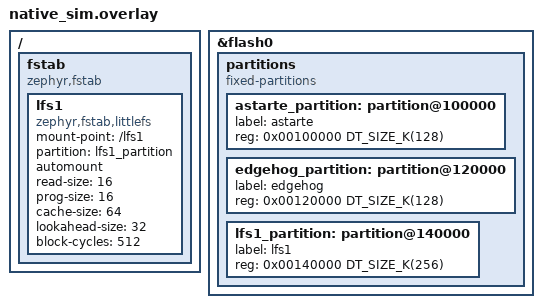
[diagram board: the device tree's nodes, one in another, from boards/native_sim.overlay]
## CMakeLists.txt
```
# (C) Copyright 2024, SECO Mind Srl
#
# SPDX-License-Identifier: Apache-2.0

cmake_minimum_required(VERSION 3.20.0)

function(concat_if_exists FILE_PATH STRING_NAME)
    # Check if the file exists
    file(GLOB FILE_TO_ADD ${FILE_PATH})

    # If the file exists, add it to the list
    if(EXISTS ${FILE_TO_ADD})
        set(${STRING_NAME} "${${STRING_NAME}};${FILE_PATH}" PARENT_SCOPE)
    endif()
endfunction()

set(CMAKE_EXPORT_COMPILE_COMMANDS ON)

# add some custom functions from the sample directory
set(SAMPLE_DIR "${CMAKE_CURRENT_LIST_DIR}/../samples/edgehog_app")

# add the sample specific private configuration
concat_if_exists(${CMAKE_SOURCE_DIR}/private.conf EXTRA_CONF_FILE)

find_package(Zephyr REQUIRED HINTS $ENV{ZEPHYR_BASE})
project(e2e_test)

if(CONFIG_FILE_SYSTEM_LITTLEFS)
    zephyr_library_link_libraries(LITTLEFS)
endif()

# add sources and includes from the sample dir
target_sources(app PRIVATE ${SAMPLE_DIR}/src/eth.c)
target_include_directories(app PRIVATE ${SAMPLE_DIR}/src/include)

# Generate the key/certificate pair for the HTTP server if not already present
set(CERT_OUT "${CMAKE_CURRENT_SOURCE_DIR}/${CONFIG_E2E_HTTP_SERVER_CERT_DIR}/192.0.2.2.pem")
set(KEY_OUT "${CMAKE_CURRENT_SOURCE_DIR}/${CONFIG_E2E_HTTP_SERVER_CERT_DIR}/192.0.2.2.key")
set(CERT_CONFIG "${CMAKE_CURRENT_SOURCE_DIR}/${CONFIG_E2E_HTTP_SERVER_CERT_DIR}/cert_config.cnf")

message(STATUS "Generating self-signed certificate and key...")
execute_process(
    COMMAND openssl req -x509 -new -nodes
            -keyout "${KEY_OUT}"
            -out "${CERT_OUT}"
            -days 3650
            -config "${CERT_CONFIG}"
    RESULT_VARIABLE openssl_result
)
if(NOT openssl_result EQUAL "0")
    message(FATAL_ERROR "Failed to generate certificates with OpenSSL")
endif()

# handle generating certificate inc file
include(certificate.cmake)
if(CONFIG_E2E_ASTARTE_TLS_CERTIFICATE_PATH)
    generate_certificate_inc(${CONFIG_E2E_ASTARTE_TLS_CERTIFICATE_PATH} "astarte_root_certificate")
endif()
if(CONFIG_E2E_EDGEHOG_OTA_TLS_CERTIFICATE_PATH)
    generate_certificate_inc(${CONFIG_E2E_EDGEHOG_OTA_TLS_CERTIFICATE_PATH} "edgehog_ota_root_certificate")
endif()
generate_certificate_inc("${CONFIG_E2E_HTTP_SERVER_CERT_DIR}/192.0.2.2.pem" "edgehog_ft_root_certificate")

# add astarte private headers
target_include_directories(app PRIVATE ${CMAKE_SOURCE_DIR}/../lib/edgehog_device/include)

# add sources
FILE(GLOB app_sources src/*.c)
target_sources(app PRIVATE ${app_sources})
target_include_directories(app PRIVATE include)
```

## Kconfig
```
# (C) Copyright 2024, SECO Mind Srl
#
# SPDX-License-Identifier: Apache-2.0

menu "Zephyr"
source "Kconfig.zephyr"
endmenu

rsource "../Kconfig"

menu "End to end test"

config E2E_ASTARTE_TLS_CERTIFICATE_PATH
	string "Path of the tls root Astarte certificate"
	help
	  Path to a certificate in PEM format. It will be included in the binary and used for TLS
	  authentication with Astarte.
	  This path should be relative to the end to end project folder.

config E2E_EDGEHOG_OTA_TLS_CERTIFICATE_PATH
	string "Path of the tls root Edgehog certificate for OTA"
	help
	  Path to a certificate in PEM format. It will be included in the binary and used for TLS
	  authentication with Edgehog.
	  This path should be relative to the end to end project folder.

config E2E_ASTARTE_DEVICE_ID
	string "Astarte device ID"
    default ""
	help
	  Device ID to be used to connect to Astarte.

config E2E_ASTARTE_CREDENTIAL_SECRET
    string "Astarte credential secret"
    default ""
    help
        The credential secret to be used to connect to Astarte.

config E2E_HTTP_SERVER_DATA_DIR
    string "Directory for HTTP server data"
    default "http_server_data"
    help
        Directory where the HTTP server will store its data.

config E2E_HTTP_SERVER_CERT_DIR
    string "Directory for HTTP server certificates"
    default "http_server_certs"
    help
        Directory where the HTTP server will store its certificates.

config E2E_HTTP_SERVER_PORT
    int "HTTP server port"
    default 8443
    help
        Port on which the HTTP server will listen.

config E2E_APPENGINE_TOKEN
	string "Token to access appengine APIs"
    default ""
	help
	  Token used to access the Astarte appengine APIs.

config E2E_APPENGINE_URL
    string "Url of the appengine APIs"
    default ""
    help
        Url of the appengine APIs exposed by astarte

config E2E_LOG_ONLY
    bool "Enable device log only mode"
    default n
    help
        Incoming astarte server messages will only be logged and no check will be
        performed against incoming data

config E2E_DEVICE_THREAD_STACK_SIZE
    int "Device thread stack size (Bytes)"
    default 8192
    help
        Use this setting to change the size of the stack for the thread running the Astarte device.

config E2E_DEVICE_THREAD_PRIORITY
    int "Device thread priority"
    default 0
    help
        Use this setting to change the priority of the thread running the Astarte device.

config E2E_ETH_POLL_PERIOD_MS
    int "Device thread polling period (ms)"
    default 100
    help
        Use this setting to change the polling period for the ethernet connection.

config E2E_MQTT_CONNECTION_TIMEOUT_MS
    int "MQTT connection timeout (ms)"
    default 3000
    help
        Use this setting to change the MQTT connection timeout.

config E2E_MQTT_POLL_TIMEOUT_MS
    int "MQTT subsequent polling timeout (ms)"
    default 200
    help
        Use this setting to change the MQTT polling timeout.

config E2E_HTTP_TIMEOUT_MS
    int "HTTP operations timeout (ms)"
    default 3000
    help
        Use this setting to change the timeout for HTTP requests.

menu "Logging options"

module = APP
module-str = APP
source "subsys/logging/Kconfig.template.log_config"

module = RUNNER
module-str = Log level for e2e runner and command handler
module-help = Sets log level for e2e runner and command handler
source "subsys/logging/Kconfig.template.log_config"

module = UTILITIES
module-str = Log level for e2e utilities functions
module-help = Sets log level for e2e utilities functions
source "subsys/logging/Kconfig.template.log_config"

module = SHELL_HANDLERS
module-str = Log level for shell handlers
module-help = Sets log level for zephyr shell handlers
source "subsys/logging/Kconfig.template.log_config"

module = DEVICE_HANDLER
module-str = Log level for device handler
module-help = Sets log level for zephyr device handler
source "subsys/logging/Kconfig.template.log_config"

endmenu

endmenu
```

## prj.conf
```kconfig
# (C) Copyright 2024, SECO Mind Srl
#
# SPDX-License-Identifier: Apache-2.0
#
# This is a Kconfig fragment which can be used to enable debug-related options
# in the application. See the README for more details.

# Increase size for heap allocation space
CONFIG_COMMON_LIBC_MALLOC_ARENA_SIZE=196608

# Increase the UART RX ring buffer to handle long automated commands
CONFIG_SHELL_BACKEND_SERIAL_RX_RING_BUFFER_SIZE=1024
# Ensure the shell command buffer is large enough
CONFIG_SHELL_CMD_BUFF_SIZE=1024
# Prevent the terminal from line-wrapping the echo, which breaks Twister's regex
CONFIG_SHELL_DEFAULT_TERMINAL_WIDTH=1024

# Increase the system workqueue stack
CONFIG_SYSTEM_WORKQUEUE_STACK_SIZE=4096

CONFIG_SHELL=y
CONFIG_SHELL_BACKEND_SERIAL=y
CONFIG_SHELL_BACKEND_SERIAL_LOG_LEVEL_DBG=y

CONFIG_E2E_ASTARTE_TLS_CERTIFICATE_PATH="certificate/astarte.pem"
CONFIG_E2E_EDGEHOG_OTA_TLS_CERTIFICATE_PATH="certificate/edgehog-ota.pem"

CONFIG_DEBUG_OPTIMIZATIONS=y
CONFIG_MBEDTLS_DEBUG=y

# Enable logging with floating point support
CONFIG_LOG=y
CONFIG_CBPRINTF_FP_SUPPORT=y

# Increase minimum heap size.
# TODO: set back the value to 4096 once the file transfer download will not require heap allocation
CONFIG_HEAP_MEM_POOL_SIZE=12288

# Increased stack size
CONFIG_MAIN_STACK_SIZE=16384

# Use custom heap
CONFIG_ASTARTE_DEVICE_SDK_ENABLE_HEAP=y

# Enable base64 encoding and decoding
CONFIG_BASE64=y

# Enable system hashmaps
CONFIG_SYS_HASH_MAP=y
CONFIG_SYS_HASH_FUNC32=y

# Enable JSON library
CONFIG_JSON_LIBRARY=y

# Enable entropy generator
CONFIG_ENTROPY_GENERATOR=y

# DNS resolver
CONFIG_DNS_RESOLVER=y
CONFIG_DNS_SERVER_IP_ADDRESSES=y
CONFIG_DNS_SERVER1="8.8.8.8" # Google DNS

# Base MbedTLS & heap configuration
CONFIG_MBEDTLS=y
CONFIG_MBEDTLS_BUILTIN=y
CONFIG_MBEDTLS_ENABLE_HEAP=y
CONFIG_MBEDTLS_HEAP_SIZE=95000

# Enable PSA Crypto Backend
CONFIG_PSA_CRYPTO=y
CONFIG_PSA_CRYPTO_ENABLE_ALL=y
CONFIG_MBEDTLS_PSA_CRYPTO_C=y

# TLS & X.509
CONFIG_MBEDTLS_SSL_MAX_CONTENT_LEN=8192
CONFIG_MBEDTLS_PEM_PARSE_C=y
CONFIG_MBEDTLS_PEM_WRITE_C=y
CONFIG_MBEDTLS_BASE64_C=y
CONFIG_MBEDTLS_PK_WRITE_C=y
CONFIG_MBEDTLS_SSL_PROTO_TLS1_2=y
CONFIG_MBEDTLS_SSL_SERVER_NAME_INDICATION=y
CONFIG_MBEDTLS_X509_USE_C=y
CONFIG_MBEDTLS_X509_CRT_PARSE_C=y
CONFIG_MBEDTLS_X509_CRL_PARSE_C=y
CONFIG_MBEDTLS_X509_CSR_PARSE_C=y
CONFIG_MBEDTLS_X509_CSR_WRITE_C=y
CONFIG_MBEDTLS_PKCS5_C=y
CONFIG_MBEDTLS_KEY_EXCHANGE_ECDHE_ECDSA_ENABLED=y
CONFIG_MBEDTLS_KEY_EXCHANGE_ECDHE_RSA_ENABLED=y

# Enable networking
CONFIG_NETWORKING=y

# Sockets
CONFIG_NET_SOCKETS=y
CONFIG_NET_SOCKETS_SOCKOPT_TLS=y

# Use DHCP for IPv4 and IPv6
CONFIG_NET_DHCPV4=y
CONFIG_NET_DHCPV6=y

# Generic networking options
CONFIG_NET_TX_STACK_SIZE=4096
CONFIG_NET_RX_STACK_SIZE=4096
CONFIG_NET_PKT_RX_COUNT=20
CONFIG_NET_PKT_TX_COUNT=20
CONFIG_NET_BUF_RX_COUNT=40
CONFIG_NET_BUF_TX_COUNT=40
CONFIG_NET_MAX_CONTEXTS=20
CONFIG_NET_MAX_CONN=6
CONFIG_NET_MGMT=y
CONFIG_NET_MGMT_EVENT=y
CONFIG_NET_IPV4=y
CONFIG_NET_IPV6=y
CONFIG_NET_TCP=y

# Enable HTTP client
CONFIG_HTTP_CLIENT=y

# MQTT options
CONFIG_MQTT_LIB=y
CONFIG_MQTT_LIB_TLS=y
CONFIG_MQTT_KEEPALIVE=60

# Enable flash
CONFIG_FLASH=y
CONFIG_FLASH_MAP=y
CONFIG_FLASH_PAGE_LAYOUT=y

# Enable NVS
CONFIG_NVS=y
CONFIG_NVS_LOG_LEVEL_WRN=y

# Enable storage
CONFIG_ZMS=y
CONFIG_ZMS_LOG_LEVEL_WRN=y

# Enable hash functions
CONFIG_SYS_HASH_FUNC32=y
CONFIG_SYS_HASH_FUNC32_MURMUR3=y

# Astarte device SDK
CONFIG_ASTARTE_DEVICE_SDK=y
CONFIG_ASTARTE_DEVICE_SDK_HOSTNAME="."
# The two certificate tags are the same as the root CA is the same for Astarte API and MQTT broker.
CONFIG_ASTARTE_DEVICE_SDK_HTTPS_CA_CERT_TAG=1
CONFIG_ASTARTE_DEVICE_SDK_MQTTS_CA_CERT_TAG=1
CONFIG_ASTARTE_DEVICE_SDK_CLIENT_CERT_TAG=2
CONFIG_ASTARTE_DEVICE_SDK_PAIRING_JWT=""
CONFIG_ASTARTE_DEVICE_SDK_REALM_NAME="."

# Edgehog depends on
CONFIG_IMG_MANAGER=y
CONFIG_STREAM_FLASH=y
CONFIG_REBOOT=y

# Edgehog device
CONFIG_EDGEHOG_DEVICE=y
CONFIG_EDGEHOG_DEVICE_OTA_HTTPS_CA_CERT_TAG=3
CONFIG_EDGEHOG_DEVICE_ZBUS_OTA_EVENT=y

# System info interface data
CONFIG_EDGEHOG_DEVICE_PART_NUMBER=""
CONFIG_EDGEHOG_DEVICE_SERIAL_NUMBER=""

# Sample configuration
CONFIG_E2E_ASTARTE_CREDENTIAL_SECRET="."
CONFIG_E2E_ASTARTE_DEVICE_ID="......................"

CONFIG_DNS_RESOLVER_AI_MAX_ENTRIES=4
CONFIG_NET_SOCKETS_TLS_MAX_CONTEXTS=4
CONFIG_TLS_MAX_CREDENTIALS_NUMBER=8

CONFIG_THREAD_MONITOR=y
CONFIG_INIT_STACKS=y
CONFIG_THREAD_STACK_INFO=y

CONFIG_ZVFS_OPEN_MAX=26

CONFIG_SNTP=y
CONFIG_NET_CONFIG_CLOCK_SNTP_INIT=y
CONFIG_NET_CONFIG_SNTP_INIT_SERVER="0.pool.ntp.org"
CONFIG_NET_CONFIG_SNTP_INIT_TIMEOUT=3000

# Enable the settings
CONFIG_SETTINGS=y

# Activate Zbus
CONFIG_ZBUS=y

# Activate thread naming
CONFIG_THREAD_NAME=y

# Enable File System and LittleFS
CONFIG_FILE_SYSTEM=y
CONFIG_FILE_SYSTEM_LITTLEFS=y

# Enable UUID
CONFIG_UUID=y
CONFIG_UUID_V4=y
CONFIG_UUID_V5=y
CONFIG_UUID_BASE64=y

# Enable LZ4 compression
CONFIG_LZ4=y
CONFIG_LZ4_FRAME_SUPPORT=y

# Enable scoped cleanup helpers
CONFIG_SCOPE_CLEANUP_HELPERS=y
```

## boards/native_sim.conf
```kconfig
# (C) Copyright 2024, SECO Mind Srl
#
# SPDX-License-Identifier: Apache-2.0

CONFIG_LOG_BACKEND_NATIVE_POSIX=n
CONFIG_UART_NATIVE_PTY_0_ON_STDINOUT=y

CONFIG_PICOLIBC_USE_MODULE=y
CONFIG_PICOLIBC=y

# Print logs immediately to catch fatal errors before exit
CONFIG_LOG_MODE_IMMEDIATE=y

# Ethernet settings
CONFIG_NET_L2_ETHERNET=y
CONFIG_NET_L2_ETHERNET_MGMT=y

# Network application options and configuration
CONFIG_NET_DHCPV4=n
CONFIG_NET_DHCPV6=n
CONFIG_NET_CONFIG_SETTINGS=y
CONFIG_NET_CONFIG_NEED_IPV6=y
CONFIG_NET_CONFIG_MY_IPV6_ADDR="2001:db8::1"
CONFIG_NET_CONFIG_PEER_IPV6_ADDR="2001:db8::2"
CONFIG_NET_CONFIG_NEED_IPV4=y
CONFIG_NET_CONFIG_MY_IPV4_ADDR="192.0.2.1"
CONFIG_NET_CONFIG_PEER_IPV4_ADDR="192.0.2.2"
CONFIG_NET_CONFIG_MY_IPV4_GW="192.0.2.2"
```

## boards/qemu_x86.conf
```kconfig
# (C) Copyright 2026, SECO Mind Srl
#
# SPDX-License-Identifier: Apache-2.0

# Provide enough stack space for MbedTLS crypto and HTTPS handshakes
CONFIG_E2E_DEVICE_THREAD_STACK_SIZE=16384
CONFIG_SHELL_STACK_SIZE=16384

# Enable the simulated flash driver for NVS
CONFIG_FLASH_SIMULATOR=y

# Print logs immediately to catch fatal errors before exit
CONFIG_LOG_MODE_IMMEDIATE=y

# Enable PCIe bus to support the e1000 driver
CONFIG_PCIE=y

# QEMU Ethernet settings (emulated e1000)
CONFIG_NET_L2_ETHERNET=y
CONFIG_ETH_E1000=y

# Enable the QEMU network backend
CONFIG_NET_QEMU_ETHERNET=y

# Network application options and configuration
CONFIG_NET_DHCPV4=n
CONFIG_NET_DHCPV6=n
CONFIG_NET_CONFIG_SETTINGS=y
CONFIG_NET_CONFIG_NEED_IPV6=y
CONFIG_NET_CONFIG_MY_IPV6_ADDR="2001:db8::1"
CONFIG_NET_CONFIG_PEER_IPV6_ADDR="2001:db8::2"
CONFIG_NET_CONFIG_NEED_IPV4=y
CONFIG_NET_CONFIG_MY_IPV4_ADDR="192.0.2.1"
CONFIG_NET_CONFIG_PEER_IPV4_ADDR="192.0.2.2"
CONFIG_NET_CONFIG_MY_IPV4_GW="192.0.2.2"
```

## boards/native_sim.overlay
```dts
/*
 * (C) Copyright 2024, SECO Mind Srl
 *
 * SPDX-License-Identifier: Apache-2.0
 */

 / {
	fstab {
		compatible = "zephyr,fstab";
		lfs1: lfs1 {
			compatible = "zephyr,fstab,littlefs";
			mount-point = "/lfs1";
			partition = <&lfs1_partition>;
			automount;
			read-size = <16>;
			prog-size = <16>;
			cache-size = <64>;
			lookahead-size = <32>;
			block-cycles = <512>;
		};
	};
};

&flash0 {
	partitions {
        compatible = "fixed-partitions";
        #address-cells = <1>;
        #size-cells = <1>;

		astarte_partition: partition@100000 {
			label = "astarte";
			reg = <0x00100000 DT_SIZE_K(128)>;
		};
		edgehog_partition: partition@120000 {
			label = "edgehog";
			reg = <0x00120000 DT_SIZE_K(128)>;
		};
		lfs1_partition: partition@140000 {
			label = "lfs1";
			reg = <0x00140000 DT_SIZE_K(256)>;
		};
	};
};
```

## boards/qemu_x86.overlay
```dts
/*
 * (C) Copyright 2026, SECO Mind Srl
 *
 * SPDX-License-Identifier: Apache-2.0
 */

/ {
	fstab {
		compatible = "zephyr,fstab";
		lfs1: lfs1 {
			compatible = "zephyr,fstab,littlefs";
			mount-point = "/lfs1";
			partition = <&lfs1_partition>;
			automount;
			read-size = <16>;
			prog-size = <16>;
			cache-size = <64>;
			lookahead-size = <32>;
			block-cycles = <512>;
		};
	};
};

&flash_sim0 {
	partitions {
        compatible = "fixed-partitions";
        #address-cells = <1>;
        #size-cells = <1>;

		astarte_partition: partition@41000 {
			label = "astarte";
			reg = <0x00041000 0x00010000>;
		};
		edgehog_partition: partition@51000 {
			label = "edgehog";
			reg = <0x00051000 0x00010000>;
		};
		lfs1_partition: partition@61000 {
			label = "lfs1";
			reg = <0x00061000 0x00040000>;
		};
	};
};
```

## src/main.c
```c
/*
 * (C) Copyright 2024, SECO Mind Srl
 *
 * SPDX-License-Identifier: Apache-2.0
 */

#include <zephyr/kernel.h>
#include <zephyr/logging/log.h>
#include <zephyr/net/sntp.h>
#include <zephyr/sys/atomic.h>
#include <zephyr/sys/clock.h>
#include <zephyr/sys/util.h>

#if defined(CONFIG_ARCH_POSIX)
#include <nsi_main.h>
#endif

#if !defined(CONFIG_ASTARTE_DEVICE_SDK_DEVELOP_USE_NON_TLS_HTTP)                                   \
    || !defined(CONFIG_ASTARTE_DEVICE_SDK_DEVELOP_USE_NON_TLS_MQTT)                                \
    || !!defined(CONFIG_EDGEHOG_DEVICE_DEVELOP_USE_NON_TLS_HTTP)
#define NEEDS_TLS
#endif

#if defined(NEEDS_TLS)

// Enable mbed tls debug
#define MBEDTLS_DEBUG_C

#if defined(CONFIG_E2E_ASTARTE_TLS_CERTIFICATE_PATH)
#include "e2e_ca_certificates.h"
#else
#error TLS enabled but no generated certificate found: check the CONFIG_E2E_ASTARTE_TLS_CERTIFICATE_PATH option
#endif

#include <mbedtls/debug.h>
#include <zephyr/net/tls_credentials.h>

#endif

#include "eth.h"

#include "runner.h"
#include "utilities.h"

LOG_MODULE_REGISTER(main, CONFIG_APP_LOG_LEVEL);

/************************************************
 *       Checks over configuration values       *
 ***********************************************/

/************************************************
 *   Constants, static variables and defines    *
 ***********************************************/

#define ETH_THREAD_STACK_SIZE 4096
K_THREAD_STACK_DEFINE(eth_thread_stack_area, ETH_THREAD_STACK_SIZE);
static struct k_thread eth_thread_data;
enum eth_thread_flags
{
    ETH_THREAD_TERMINATION_FLAG = 0,
};
static atomic_t eth_thread_flags;

/************************************************
 *         Static functions declaration         *
 ***********************************************/

static void system_time_init(void);
static void eth_thread_entry_point(void *unused1, void *unused2, void *unused3);

/************************************************
 *         Global functions definition          *
 ***********************************************/

int main(void)
{
    LOG_INF("Edgehog device end to end test");

    // Initialize Ethernet driver
    LOG_INF("Initializing Ethernet driver.");
    if (eth_connect() != 0) {
        LOG_ERR("Connectivity intialization failed!");
        return -1;
    }

#if defined(NEEDS_TLS)

    // Add TLS certificate
    tls_credential_add(CONFIG_ASTARTE_DEVICE_SDK_HTTPS_CA_CERT_TAG, TLS_CREDENTIAL_CA_CERTIFICATE,
        astarte_ca_certificate_root, ARRAY_SIZE(astarte_ca_certificate_root));

    tls_credential_add(CONFIG_EDGEHOG_DEVICE_OTA_HTTPS_CA_CERT_TAG, TLS_CREDENTIAL_CA_CERTIFICATE,
        edgehog_ota_ca_certificate_root, sizeof(edgehog_ota_ca_certificate_root));

#ifdef CONFIG_EDGEHOG_DEVICE_FILE_TRANSFER_HTTPS_CA_CERT_TAG
    tls_credential_add(CONFIG_EDGEHOG_DEVICE_FILE_TRANSFER_HTTPS_CA_CERT_TAG,
        TLS_CREDENTIAL_CA_CERTIFICATE, edgehog_ft_ca_certificate_root,
        sizeof(edgehog_ft_ca_certificate_root));
#endif

    // Enable mbedtls logging
    mbedtls_debug_set_threshold(1);

#endif

    LOG_INF("Spawning a new thread to poll the eth interface and check connectivity.");
    k_thread_create(&eth_thread_data, eth_thread_stack_area,
        K_THREAD_STACK_SIZEOF(eth_thread_stack_area), eth_thread_entry_point, NULL, NULL, NULL,
        CONFIG_E2E_DEVICE_THREAD_PRIORITY, 0, K_NO_WAIT);

    system_time_init();

    LOG_INF("Running the end to end test.");
    run_end_to_end_test();

    atomic_set_bit(&eth_thread_flags, ETH_THREAD_TERMINATION_FLAG);
    CHECK_HALT(k_thread_join(&eth_thread_data, K_FOREVER) != 0,
        "Failed in waiting for the eth polling thread to terminate.");

    LOG_INF("Returning from the end to end test.");

#if defined(CONFIG_ARCH_POSIX)
    // Required to terminate when on posix
    nsi_exit(0);
#endif
    return 0;
}

/************************************************
 *         Static functions definitions         *
 ***********************************************/

static void system_time_init()
{
#ifdef CONFIG_SNTP
    int ret = 0;
    struct sntp_time now;
    struct timespec tspec;

    LOG_INF("Attempting to sync time via SNTP from %s...", CONFIG_NET_CONFIG_SNTP_INIT_SERVER);

    ret = sntp_simple(
        CONFIG_NET_CONFIG_SNTP_INIT_SERVER, CONFIG_NET_CONFIG_SNTP_INIT_TIMEOUT, &now);
    if (ret == 0) {
        tspec.tv_sec = (time_t) now.seconds;
        // NOLINTBEGIN(bugprone-narrowing-conversions, hicpp-signed-bitwise,
        // readability-magic-numbers)
        tspec.tv_nsec = ((uint64_t) now.fraction * (1000lu * 1000lu * 1000lu)) >> 32;
        // NOLINTEND(bugprone-narrowing-conversions, hicpp-signed-bitwise,
        // readability-magic-numbers)
        sys_clock_settime(SYS_CLOCK_REALTIME, &tspec);

        LOG_INF("SNTP sync successful! System time set to: %lld seconds", (long long) tspec.tv_sec);
    } else {
        LOG_ERR("Failed to get time from SNTP server, error: %d", ret);
    }
#endif
}

static void eth_thread_entry_point(void *unused1, void *unused2, void *unused3)
{
    ARG_UNUSED(unused1);
    ARG_UNUSED(unused2);
    ARG_UNUSED(unused3);

    LOG_INF("Started the eth polling thread");

    while (!atomic_test_bit(&eth_thread_flags, ETH_THREAD_TERMINATION_FLAG)) {
        k_timepoint_t timepoint = sys_timepoint_calc(K_MSEC(CONFIG_E2E_ETH_POLL_PERIOD_MS));

        if (eth_poll() != 0) {
            LOG_ERR("Failed polling Ethernet."); // NOLINT
        }

        k_sleep(sys_timepoint_timeout(timepoint));
    }
}
```

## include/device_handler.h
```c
/*
 * (C) Copyright 2025, SECO Mind Srl
 *
 * SPDX-License-Identifier: Apache-2.0
 */

#ifndef DEVICE_HANDLER_H
#define DEVICE_HANDLER_H

#include "utilities.h"

void setup_device();
void free_device();
void wait_for_device_connection();
void disconnect_device();
void wait_for_device_disconnection();

#endif /* DEVICE_HANDLER_H */
```

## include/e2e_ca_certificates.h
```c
/*
 * (C) Copyright 2024, SECO Mind Srl
 *
 * SPDX-License-Identifier: Apache-2.0
 */

#ifndef E2E_CA_CERTIFICATES_H
#define E2E_CA_CERTIFICATES_H

// astarte_root_certificate.inc is generated at build time by certificate.cmake
static const unsigned char astarte_ca_certificate_root[] = {
#include "astarte_root_certificate.inc"
    0x00
};

// GTS Root R1
static const unsigned char edgehog_ota_ca_certificate_root[] = {
#include "edgehog_ota_root_certificate.inc"
    0x00
};

// Auto signed certificate for FT server
static const unsigned char edgehog_ft_ca_certificate_root[] = {
#include "edgehog_ft_root_certificate.inc"
    0x00
};

#endif /* E2E_CA_CERTIFICATES_H */
```

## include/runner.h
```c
/*
 * (C) Copyright 2024, SECO Mind Srl
 *
 * SPDX-License-Identifier: Apache-2.0
 */

#ifndef RUNNER_H
#define RUNNER_H

// Run the end to end test, this function will block untill the test has been completed
void run_end_to_end_test();

#endif /* RUNNER_H */
```

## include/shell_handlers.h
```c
/*
 * (C) Copyright 2025, SECO Mind Srl
 *
 * SPDX-License-Identifier: Apache-2.0
 */

#ifndef SHELL_HANDLERS_H
#define SHELL_HANDLERS_H

#endif /* SHELL_HANDLERS_H */
```

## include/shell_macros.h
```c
/*
 * (C) Copyright 2026, SECO Mind Srl
 *
 * SPDX-License-Identifier: Apache-2.0
 */

#ifndef SHELL_MACROS_H
#define SHELL_MACROS_H

#define SHELL_IS_READY "dvcshellcmd Device shell ready"
#define SHELL_IS_CLOSING "dvcshellcmd Device shell closing"

#endif /* SHELL_MACROS_H */
```

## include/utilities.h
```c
/*
 * (C) Copyright 2024, SECO Mind Srl
 *
 * SPDX-License-Identifier: Apache-2.0
 */

#ifndef UTILITIES_H
#define UTILITIES_H

#include <zephyr/fatal.h>
#include <zephyr/logging/log.h>
#include <zephyr/shell/shell.h>

#include "edgehog_device/result.h"

#define CHECK_HALT(expr, ...)                                                                      \
    do {                                                                                           \
        if (unlikely(expr)) {                                                                      \
            __VA_OPT__(LOG_ERR(__VA_ARGS__);)                                                      \
            k_fatal_halt(-1);                                                                      \
        }                                                                                          \
    } while (0)

#define CHECK_EDGEHOG_OK_HALT(expr, ...) CHECK_HALT(expr != EDGEHOG_RESULT_OK, __VA_ARGS__)

#define CHECK_RET_1(expr, ...)                                                                     \
    do {                                                                                           \
        if (unlikely(expr)) {                                                                      \
            __VA_OPT__(LOG_ERR(__VA_ARGS__);)                                                      \
            return 1;                                                                              \
        }                                                                                          \
    } while (0)

#define CHECK_EDGEHOG_OK_RET_1(expr, ...) CHECK_RET_1(expr != EDGEHOG_RESULT_OK, __VA_ARGS__)

#define CHECK_GOTO(expr, label, ...)                                                               \
    do {                                                                                           \
        if (unlikely(expr)) {                                                                      \
            __VA_OPT__(LOG_ERR(__VA_ARGS__);)                                                      \
            goto label;                                                                            \
        }                                                                                          \
    } while (0)

#define CHECK_EDGEHOG_OK_GOTO(expr, label, ...)                                                    \
    CHECK_GOTO(expr != EDGEHOG_RESULT_OK, label, __VA_ARGS__)

#endif /* UTILITIES_H */
```

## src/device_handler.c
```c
/*
 * (C) Copyright 2025, SECO Mind Srl
 *
 * SPDX-License-Identifier: Apache-2.0
 */

#include "device_handler.h"

#include <zephyr/kernel.h>
#include <zephyr/logging/log.h>
#include <zephyr/sys/atomic.h>

#include <edgehog_device/device.h>
#include <edgehog_device/file_transfer.h>
#include <edgehog_device/storage.h>

#include "utilities.h"

LOG_MODULE_REGISTER(device_handler, CONFIG_DEVICE_HANDLER_LOG_LEVEL);

/************************************************
 *   Constants, static variables and defines    *
 ***********************************************/

#define GENERIC_WAIT_SLEEP_500_MS 500

static edgehog_device_handle_t device_handle = NULL;

K_THREAD_STACK_DEFINE(device_thread_stack_area, CONFIG_E2E_DEVICE_THREAD_STACK_SIZE);
static struct k_thread device_thread_data;
static atomic_t device_thread_flags;
enum device_thread_flags
{
    DEVICE_THREAD_CONNECTED_FLAG = 0,
    DEVICE_THREAD_TERMINATION_FLAG,
};

// Large static buffer to hold the loopback payload in memory
#define MAX_LOOPBACK_FILE_SIZE 32768
static uint8_t loopback_file_buffer[MAX_LOOPBACK_FILE_SIZE];
static size_t loopback_file_size = 0;

K_THREAD_STACK_DEFINE(download_thread_stack_area, 2048);
static struct k_thread download_thread_data;

K_THREAD_STACK_DEFINE(upload_thread_stack_area, 2048);
static struct k_thread upload_thread_data;

/************************************************
 *         Static functions declaration         *
 ***********************************************/

static void device_thread_entry_point(void *unused1, void *unused2, void *unused3);
static void edgehog_event_callback(astarte_device_event_t event, void *user_data);
static void download_thread_entry_point(void *stream_pipe, void *stream_event, void *unused3);
static void upload_thread_entry_point(void *stream_pipe, void *stream_event, void *unused3);

/************************************************
 *     Callbacks definition and declaration     *
 ***********************************************/

static bool on_stream_transfer_start(
    const char *name, edgehog_ft_type_t type, size_t *expected_size, edgehog_ft_stream_t *stream)
{
    if (strcmp(name, "loopback") == 0) {
        // Only one file transfer can be active at a time
        struct k_pipe *pipe = stream->pipe;
        struct k_event *event = stream->event;

        if (type == EDGEHOG_FT_TYPE_SERVER_TO_DEVICE) {
            LOG_INF("Starting stream transfer [server-to-device] on pipe '%s'. Expected size: %zu "
                    "bytes",
                name, *expected_size);

            // Spawn the download thread on demand
            k_thread_create(&download_thread_data, download_thread_stack_area,
                K_THREAD_STACK_SIZEOF(download_thread_stack_area), download_thread_entry_point,
                (void *) pipe, (void *) event, NULL, CONFIG_E2E_DEVICE_THREAD_PRIORITY, 0,
                K_NO_WAIT);
        } else {
            *expected_size = loopback_file_size;

            LOG_INF("Starting stream transfer [device-to-server] on pipe '%s'. Expected size: %zu "
                    "bytes",
                name, *expected_size);

            // Spawn the upload thread on demand
            k_thread_create(&upload_thread_data, upload_thread_stack_area,
                K_THREAD_STACK_SIZEOF(upload_thread_stack_area), upload_thread_entry_point,
                (void *) pipe, (void *) event, NULL, CONFIG_E2E_DEVICE_THREAD_PRIORITY, 0,
                K_NO_WAIT);
        }

        return true;
    }

    LOG_WRN("Rejected stream transfer for unknown path/name: %s", name);
    return false; // Reject the transfer
}

static void on_filesystem_transfer_done(edgehog_ft_type_t type, const char *file_path)
{
    if (type == EDGEHOG_FT_TYPE_SERVER_TO_DEVICE) {
        LOG_INF(
            "Filesystem transfer complete [server-to-device]: file downloaded to '%s'", file_path);
    } else if (type == EDGEHOG_FT_TYPE_DEVICE_TO_SERVER) {
        LOG_INF(
            "Filesystem transfer complete [device-to-server]: file uploaded from '%s'", file_path);
    } else {
        LOG_WRN("Filesystem transfer complete: unknown transfer type for '%s'", file_path);
    }
}

static void edgehog_event_callback(astarte_device_event_t event, void *user_data)
{
    ARG_UNUSED(user_data);
    switch (event.type) {
        case ASTARTE_DEVICE_EVENT_CONNECTED:
            LOG_INF("Device connected");
            atomic_set_bit(&device_thread_flags, DEVICE_THREAD_CONNECTED_FLAG);
            break;
        case ASTARTE_DEVICE_EVENT_DISCONNECTED:
            LOG_INF("Device disconnected");
            atomic_clear_bit(&device_thread_flags, DEVICE_THREAD_CONNECTED_FLAG);
            break;
        default:
            break;
    }
}

/************************************************
 *         Global functions definition          *
 ***********************************************/

void setup_device()
{
    LOG_INF("Initializing an Edgehog device.");

    LOG_INF("Spawning a new thread to poll data from the Edgehog device.");
    k_thread_create(&device_thread_data, device_thread_stack_area,
        K_THREAD_STACK_SIZEOF(device_thread_stack_area), device_thread_entry_point, NULL, NULL,
        NULL, CONFIG_E2E_DEVICE_THREAD_PRIORITY, 0, K_NO_WAIT);

    LOG_INF("Edgehog device created.");
}

void free_device()
{
    atomic_set_bit(&device_thread_flags, DEVICE_THREAD_TERMINATION_FLAG);

    CHECK_HALT(k_thread_join(&device_thread_data, K_FOREVER) != 0,
        "Failed in waiting for the Edgehog thread to terminate.");

    LOG_INF("Destroing Edgehog device and freeing resources.");
    LOG_INF("Edgehog device destroyed.");
}

void wait_for_device_connection()
{
    while (!atomic_test_bit(&device_thread_flags, DEVICE_THREAD_CONNECTED_FLAG)) {
        k_sleep(K_MSEC(GENERIC_WAIT_SLEEP_500_MS));
    }
}

void disconnect_device()
{
    atomic_set_bit(&device_thread_flags, DEVICE_THREAD_TERMINATION_FLAG);
}

void wait_for_device_disconnection()
{
    while (atomic_test_bit(&device_thread_flags, DEVICE_THREAD_CONNECTED_FLAG)) {
        k_sleep(K_MSEC(GENERIC_WAIT_SLEEP_500_MS));
    }
}

/************************************************
 *         Static functions definitions         *
 ***********************************************/

static void device_thread_entry_point(void *unused1, void *unused2, void *unused3)
{
    ARG_UNUSED(unused1);
    ARG_UNUSED(unused2);
    ARG_UNUSED(unused3);

    edgehog_result_t eres = EDGEHOG_RESULT_OK;

    LOG_INF("Started Edgehog device thread.");

    char cred_secr[ASTARTE_PAIRING_CRED_SECR_LEN + 1] = CONFIG_E2E_ASTARTE_CREDENTIAL_SECRET;
    char device_id[ASTARTE_DEVICE_ID_LEN + 1] = CONFIG_E2E_ASTARTE_DEVICE_ID;

    astarte_device_config_t astarte_device_config = { 0 };
    astarte_device_config.http_timeout_ms = CONFIG_E2E_HTTP_TIMEOUT_MS;
    astarte_device_config.mqtt_connection_timeout_ms = CONFIG_E2E_MQTT_CONNECTION_TIMEOUT_MS;
    astarte_device_config.mqtt_poll_timeout_ms = CONFIG_E2E_MQTT_POLL_TIMEOUT_MS;
    memcpy(astarte_device_config.cred_secr, cred_secr, sizeof(cred_secr));
    memcpy(astarte_device_config.device_id, device_id, sizeof(device_id));

    // Define the allowed filesystem partition
    edgehog_ft_filesystem_partition_t ft_partitions[]
        = { { .mount_point = "/lfs1", .permissions = EDGEHOG_FT_FILESYSTEM_PERM_RW } };

    // Register /lfs1 as a user storage partition for storage-usage telemetry
    edgehog_storage_partition_t storage_partitions[]
        = { { .type = EDGEHOG_STORAGE_PARTITION_TYPE_FS, .path = "/lfs1" } };

    edgehog_device_config_t edgehog_conf = { .astarte_device_config = astarte_device_config,
        .event_cbk = edgehog_event_callback,
        .cbk_user_data = NULL,
        .telemetry_config = NULL,
        .telemetry_config_len = 0,
        .file_transfer_cbks = { .on_stream_transfer_start = on_stream_transfer_start,
            .on_filesystem_transfer_done = on_filesystem_transfer_done },
        .file_transfer_partitions = ft_partitions,
        .file_transfer_partitions_len = ARRAY_SIZE(ft_partitions),
        .storage_partitions = storage_partitions,
        .storage_partitions_len = ARRAY_SIZE(storage_partitions) };

    eres = edgehog_device_new(&edgehog_conf, &device_handle);
    if (eres != EDGEHOG_RESULT_OK) {
        LOG_ERR("Unable to create edgehog device handle");
        return;
    }

    LOG_INF("Starting Edgehog.");
    eres = edgehog_device_start(device_handle);
    if (eres != EDGEHOG_RESULT_OK) {
        LOG_ERR("Unable to start edgehog device");
        return;
    }

    while (!atomic_test_bit(&device_thread_flags, DEVICE_THREAD_TERMINATION_FLAG)) {
        k_msleep(GENERIC_WAIT_SLEEP_500_MS);
    }

    LOG_INF("Stopping Edgehog.");
    eres = edgehog_device_stop(device_handle, K_FOREVER);
    if (eres != EDGEHOG_RESULT_OK) {
        LOG_ERR("Unable to stop the edgehog device");
        goto exit;
    }

exit:

    LOG_INF("Destroying Edgehog.");
    edgehog_device_destroy(device_handle);

    LOG_INF("Exiting from the polling thread.");
}

static void download_thread_entry_point(void *stream_pipe, void *stream_event, void *unused3)
{
    ARG_UNUSED(unused3);

    LOG_INF("Started Loopback download thread (Server -> Device RAM).");

    struct k_pipe *pipe = (struct k_pipe *) stream_pipe;
    struct k_event *event = (struct k_event *) stream_event;

    loopback_file_size = 0;

    bool download_complete = false;
    while (!download_complete
        && !atomic_test_bit(&device_thread_flags, DEVICE_THREAD_TERMINATION_FLAG)) {
        uint8_t chunk[256];

        // Read progressively from the pipe provided by Edgehog
        int ret = k_pipe_read(pipe, chunk, sizeof(chunk), K_MSEC(100));
        if (ret > 0) {
            if (loopback_file_size + ret <= MAX_LOOPBACK_FILE_SIZE) {
                memcpy(loopback_file_buffer + loopback_file_size, chunk, ret);
                loopback_file_size += ret;
            } else {
                LOG_ERR("Loopback buffer overflow! Max size is %d", MAX_LOOPBACK_FILE_SIZE);
                k_event_post(event, EDGEHOG_FT_STREAM_ERROR_EVENT_FLAG);
                return;
            }
        } else if (ret < 0 && ret != -EAGAIN) {
            LOG_ERR("Failed to read from loopback pipe");
            k_event_post(event, EDGEHOG_FT_STREAM_ERROR_EVENT_FLAG);
            return;
        }

        // Check if Edgehog posted the EOF flag indicating download completion
        if (k_event_test(event, EDGEHOG_FT_STREAM_EOF_EVENT_FLAG)) {
            download_complete = true;
        }
    }

    if (!atomic_test_bit(&device_thread_flags, DEVICE_THREAD_TERMINATION_FLAG)) {
        LOG_INF("Loopback download complete: downloaded %zu bytes to RAM", loopback_file_size);
    }

    // Acknowledge that reading is complete so the library can safely tear down memory structures
    if (event) {
        k_event_post(event, EDGEHOG_FT_STREAM_ACK_EVENT_FLAG);
    }

    LOG_INF("Exiting download thread.");
}

static void upload_thread_entry_point(void *stream_pipe, void *stream_event, void *unused3)
{
    ARG_UNUSED(unused3);

    LOG_INF("Started Loopback upload thread (Device RAM -> Server).");

    struct k_pipe *pipe = (struct k_pipe *) stream_pipe;
    struct k_event *event = (struct k_event *) stream_event;

    size_t total_written = 0;

    // We only enter the upload phase if we actually received a file in the download phase
    if (loopback_file_size > 0) {
        while (total_written < loopback_file_size
            && !atomic_test_bit(&device_thread_flags, DEVICE_THREAD_TERMINATION_FLAG)) {

            // Write progressively to the pipe. This will block if the pipe is full,
            // properly syncing with the upload HTTP stream.
            int ret = k_pipe_write(pipe, loopback_file_buffer + total_written,
                loopback_file_size - total_written, K_MSEC(100));

            if (ret > 0) {
                total_written += ret;
            } else if (ret < 0 && ret != -EAGAIN) {
                LOG_ERR("Failed to write to loopback pipe");
            }
        }

        if (!atomic_test_bit(&device_thread_flags, DEVICE_THREAD_TERMINATION_FLAG)) {
            LOG_INF("Loopback upload complete: uploaded %zu bytes from RAM", total_written);
        }

        // Post EOF to inform Edgehog's read stream that there is no more data
        if (event) {
            k_event_post(event, EDGEHOG_FT_STREAM_EOF_EVENT_FLAG);
        }
    } else {
        LOG_WRN("Loopback file size is 0. Nothing to upload.");
        if (event) {
            k_event_post(event, EDGEHOG_FT_STREAM_EOF_EVENT_FLAG);
        }
    }

    LOG_INF("Exiting upload thread.");
}
```

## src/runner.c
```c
/*
 * (C) Copyright 2024, SECO Mind Srl
 *
 * SPDX-License-Identifier: Apache-2.0
 */

#include "runner.h"

#include <stdint.h>
#include <stdlib.h>
#include <string.h>

#include <zephyr/fatal.h>
#include <zephyr/kernel.h>
#include <zephyr/logging/log.h>
#include <zephyr/shell/shell.h>
#include <zephyr/shell/shell_uart.h>
#include <zephyr/sys/bitarray.h>
#include <zephyr/sys/util.h>

#include "device_handler.h"
#include "shell_handlers.h"
#include "shell_macros.h"

#include "http.h"

LOG_MODULE_REGISTER(runner, CONFIG_RUNNER_LOG_LEVEL);

/************************************************
 *         Global functions definition          *
 ***********************************************/

void run_end_to_end_test()
{
    LOG_INF("End to end test runner");

#if CONFIG_E2E_LOG_ONLY
    LOG_WRN("Running with device callbacks in log only mode");
    LOG_WRN("Data received will NOT be checked against expected data");
#endif

    LOG_INF("Starting the device");
    setup_device();

    // Wait for the device connection
    LOG_INF("Waiting for the device to be connected");
    wait_for_device_connection();

    // Wait for a second to allow the Edgehog device to perform the initial publish
    k_sleep(K_SECONDS(1));

    // We are ready to send and receive data
    const struct shell *uart_shell = shell_backend_uart_get_ptr();
    shell_start(uart_shell);
    k_sleep(K_MSEC(100));

    // Pytest detects the readyness of the shell through this string
    shell_print(uart_shell, SHELL_IS_READY);

    // Wait untill a shell command disconnects the device
    wait_for_device_disconnection();

    // Pytest detects the a termination of the test through this string
    shell_print(uart_shell, SHELL_IS_CLOSING);
    shell_stop(uart_shell);

    // Free the device and epxected data structures after `shell_stop`
    free_device();

#if CONFIG_E2E_LOG_ONLY
    LOG_WRN("Test has been run with device callbacks in log only mode");
    LOG_WRN("Data received didn't get checked against expected data");
#endif
}
```

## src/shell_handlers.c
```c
/*
 * (C) Copyright 2026, SECO Mind Srl
 *
 * SPDX-License-Identifier: Apache-2.0
 */

#include "shell_handlers.h"

#include <stdlib.h>
#include <string.h>

#include <zephyr/logging/log.h>
#include <zephyr/shell/shell.h>
#include <zephyr/sys/base64.h>

#include "device_handler.h"
#include "utilities.h"

LOG_MODULE_REGISTER(shell_handlers, CONFIG_SHELL_HANDLERS_LOG_LEVEL);

/************************************************
 *   Constants, static variables and defines    *
 ***********************************************/

#define DISCONNECT_CMD dvcshellcmd_disconnect
#define DISCONNECT_HELP "Disconnect the device and end the executable"

/************************************************
 *         Static functions declaration         *
 ***********************************************/

static int cmd_disconnect(const struct shell *sh, size_t argc, char **argv);

/************************************************
 *          Shell commands declaration          *
 ***********************************************/

SHELL_CMD_REGISTER(DISCONNECT_CMD, NULL, DISCONNECT_HELP, cmd_disconnect);

/************************************************
 *         Static functions definitions         *
 ***********************************************/

static int cmd_disconnect(const struct shell *sh, size_t argc, char **argv)
{
    ARG_UNUSED(sh);
    ARG_UNUSED(argc);
    ARG_UNUSED(argv);

    LOG_INF("Disconnect command handler");
    LOG_INF("Stopping and joining the astarte device polling thread.");
    disconnect_device();
    return 0;
}
```

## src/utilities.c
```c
/*
 * (C) Copyright 2024, SECO Mind Srl
 *
 * SPDX-License-Identifier: Apache-2.0
 */

#include "utilities.h"

#include <stdint.h>
#include <stdlib.h>
#include <string.h>

#include <zephyr/fatal.h>
#include <zephyr/logging/log.h>
#include <zephyr/shell/shell_uart.h>
#include <zephyr/sys/bitarray.h>
#include <zephyr/sys/timeutil.h>
#include <zephyr/sys/util.h>

/************************************************
 *   Constants, static variables and defines    *
 ***********************************************/

LOG_MODULE_REGISTER(utilities, CONFIG_UTILITIES_LOG_LEVEL);

/************************************************
 *         Static functions declaration         *
 ***********************************************/

/************************************************
 *         Global functions definition          *
 ***********************************************/

/************************************************
 *         Static functions definitions         *
 ***********************************************/
```
